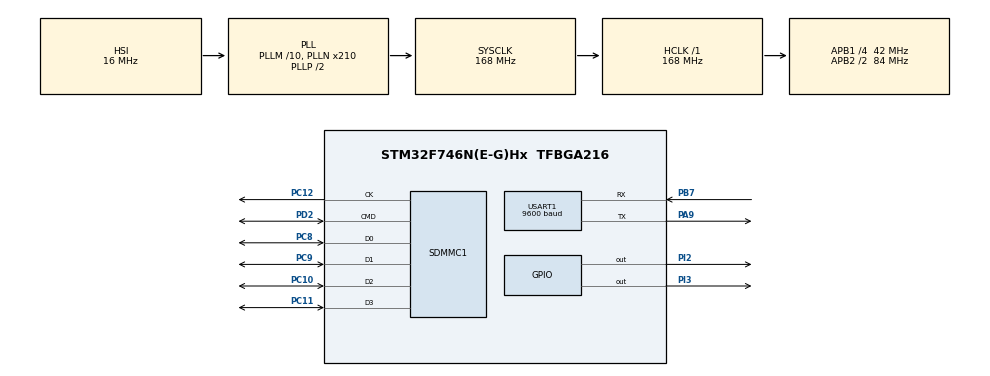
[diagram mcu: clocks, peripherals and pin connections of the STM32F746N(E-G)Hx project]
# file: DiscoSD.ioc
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FREERTOS.Tasks01=defaultTask,0,128,StartDefaultTask
Mcu.Family=STM32F7
Mcu.Name=STM32F746N(E-G)Hx
Mcu.Package=TFBGA216
NVIC.PriorityGroup=NVIC_PRIORITYGROUP_4
PA9.Mode=Asynchronous
PA9.Signal=USART1_TX
PB7.Mode=Asynchronous
PB7.Signal=USART1_RX
PC10.Mode=SD_4_bits_Wide_bus
PC10.Signal=SDMMC1_D2
PC11.Mode=SD_4_bits_Wide_bus
PC11.Signal=SDMMC1_D3
PC12.Mode=SD_4_bits_Wide_bus
PC12.Signal=SDMMC1_CK
PC8.Mode=SD_4_bits_Wide_bus
PC8.Signal=SDMMC1_D0
PC9.Mode=SD_4_bits_Wide_bus
PC9.Signal=SDMMC1_D1
PD2.Mode=SD_4_bits_Wide_bus
PD2.Signal=SDMMC1_CMD
PI2.Signal=GPIO_Output
PI3.Signal=GPIO_Output
ProjectManager.TargetToolchain=SW4STM32
RCC.AHBFreq_Value=168000000
RCC.APB1CLKDivider=RCC_HCLK_DIV4
RCC.APB1Freq_Value=42000000
RCC.APB1TimFreq_Value=84000000
RCC.APB2CLKDivider=RCC_HCLK_DIV2
RCC.APB2Freq_Value=84000000
RCC.APB2TimFreq_Value=168000000
RCC.CortexFreq_Value=168000000
RCC.HCLKFreq_Value=168000000
RCC.HSE_VALUE=25000000
RCC.HSI_VALUE=16000000
RCC.LSE_VALUE=32768
RCC.PLLM=10
RCC.PLLN=210
RCC.PLLSourceVirtual=RCC_PLLSOURCE_HSI
RCC.SYSCLKFreq_VALUE=168000000
RCC.SYSCLKSource=RCC_SYSCLKSOURCE_PLLCLK
RCC.USBFreq_Value=168000000
RCC.VCOOutputFreq_Value=336000000
SDMMC1.BusWide=SDMMC_BUS_WIDE_1B
SDMMC1.WideMode=SDMMC_BUS_WIDE_4B
USART1.BaudRate=9600
USART1.WordLength=UART_WORDLENGTH_8B
VP_FATFS_VS_SDIO.Mode=SDIO
VP_FREERTOS_VS_ENABLE.Mode=Enabled
board=STM32F746G-DISCO

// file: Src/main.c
/**
  ******************************************************************************
  * File Name          : main.c
  * Description        : Main program body
  ******************************************************************************
  *
  * COPYRIGHT(c) 2016 STMicroelectronics
  *
  * Redistribution and use in source and binary forms, with or without modification,
  * are permitted provided that the following conditions are met:
  *   1. Redistributions of source code must retain the above copyright notice,
  *      this list of conditions and the following disclaimer.
  *   2. Redistributions in binary form must reproduce the above copyright notice,
  *      this list of conditions and the following disclaimer in the documentation
  *      and/or other materials provided with the distribution.
  *   3. Neither the name of STMicroelectronics nor the names of its contributors
  *      may be used to endorse or promote products derived from this software
  *      without specific prior written permission.
  *
  * THIS SOFTWARE IS PROVIDED BY THE COPYRIGHT HOLDERS AND CONTRIBUTORS "AS IS"
  * AND ANY EXPRESS OR IMPLIED WARRANTIES, INCLUDING, BUT NOT LIMITED TO, THE
  * IMPLIED WARRANTIES OF MERCHANTABILITY AND FITNESS FOR A PARTICULAR PURPOSE ARE
  * DISCLAIMED. IN NO EVENT SHALL THE COPYRIGHT HOLDER OR CONTRIBUTORS BE LIABLE
  * FOR ANY DIRECT, INDIRECT, INCIDENTAL, SPECIAL, EXEMPLARY, OR CONSEQUENTIAL
  * DAMAGES (INCLUDING, BUT NOT LIMITED TO, PROCUREMENT OF SUBSTITUTE GOODS OR
  * SERVICES; LOSS OF USE, DATA, OR PROFITS; OR BUSINESS INTERRUPTION) HOWEVER
  * CAUSED AND ON ANY THEORY OF LIABILITY, WHETHER IN CONTRACT, STRICT LIABILITY,
  * OR TORT (INCLUDING NEGLIGENCE OR OTHERWISE) ARISING IN ANY WAY OUT OF THE USE
  * OF THIS SOFTWARE, EVEN IF ADVISED OF THE POSSIBILITY OF SUCH DAMAGE.
  *
  ******************************************************************************
  */
#include "stm32f7xx_hal.h"
#include "cmsis_os.h"
#include "fatfs.h"
#include "globalfunctions.h"

SD_HandleTypeDef hsd1;
HAL_SD_CardInfoTypedef SDCardInfo1;

//UART_HandleTypeDef huart1;

osThreadId defaultTaskHandle;

/* USER CODE BEGIN PV */
/* Private variables ---------------------------------------------------------*/

/* USER CODE END PV */

void SystemClock_Config(void);
static void MX_GPIO_Init(void);
static void MX_SDMMC1_SD_Init(void);
//static void MX_USART1_UART_Init(void);
void StartDefaultTask(void const * argument);
static void CPU_CACHE_Enable(void);

/* USER CODE BEGIN PFP */
/* Private function prototypes -----------------------------------------------*/
//static void strToUART(char * str);
/* USER CODE END PFP */

int main(void)
{
	CPU_CACHE_Enable();

  /* MCU Configuration----------------------------------------------------------*/

  /* Reset of all peripherals, Initializes the Flash interface and the Systick. */
  HAL_Init();

  /* Configure the system clock */
  SystemClock_Config();

  /* Initialize all configured peripherals */
  MX_GPIO_Init();
  MX_SDMMC1_SD_Init();
  MX_USART1_UART_Init();

  /* Create the thread(s) */
  /* definition and creation of defaultTask */
  osThreadDef(defaultTask, StartDefaultTask, osPriorityNormal, 0, 8*configMINIMAL_STACK_SIZE);
  defaultTaskHandle = osThreadCreate(osThread(defaultTask), NULL);

  /* Start scheduler */
  osKernelStart();

  /* We should never get here as control is now taken by the scheduler */

  /* Infinite loop */
  while (1)
  {

  }

}

/** System Clock Configuration
*/
void SystemClock_Config(void)
{

  RCC_OscInitTypeDef RCC_OscInitStruct;
  RCC_ClkInitTypeDef RCC_ClkInitStruct;
  RCC_PeriphCLKInitTypeDef PeriphClkInitStruct;

  __PWR_CLK_ENABLE();

  __HAL_PWR_VOLTAGESCALING_CONFIG(PWR_REGULATOR_VOLTAGE_SCALE2);

  RCC_OscInitStruct.OscillatorType = RCC_OSCILLATORTYPE_HSI;
  RCC_OscInitStruct.HSIState = RCC_HSI_ON;
  RCC_OscInitStruct.HSICalibrationValue = 16;
  RCC_OscInitStruct.PLL.PLLState = RCC_PLL_ON;
  RCC_OscInitStruct.PLL.PLLSource = RCC_PLLSOURCE_HSI;
  RCC_OscInitStruct.PLL.PLLM = 10;
  RCC_OscInitStruct.PLL.PLLN = 210;
  RCC_OscInitStruct.PLL.PLLP = RCC_PLLP_DIV2;
  RCC_OscInitStruct.PLL.PLLQ = 2;
  HAL_RCC_OscConfig(&RCC_OscInitStruct);

  RCC_ClkInitStruct.ClockType = RCC_CLOCKTYPE_HCLK|RCC_CLOCKTYPE_SYSCLK
                              |RCC_CLOCKTYPE_PCLK1|RCC_CLOCKTYPE_PCLK2;
  RCC_ClkInitStruct.SYSCLKSource = RCC_SYSCLKSOURCE_PLLCLK;
  RCC_ClkInitStruct.AHBCLKDivider = RCC_SYSCLK_DIV1;
  RCC_ClkInitStruct.APB1CLKDivider = RCC_HCLK_DIV4;
  RCC_ClkInitStruct.APB2CLKDivider = RCC_HCLK_DIV2;
  HAL_RCC_ClockConfig(&RCC_ClkInitStruct, FLASH_LATENCY_5);

  PeriphClkInitStruct.PeriphClockSelection = RCC_PERIPHCLK_USART1|RCC_PERIPHCLK_SDMMC1;
  PeriphClkInitStruct.Usart1ClockSelection = RCC_USART1CLKSOURCE_PCLK2;
  PeriphClkInitStruct.Sdmmc1ClockSelection = RCC_SDMMC1CLKSOURCE_SYSCLK;
  HAL_RCCEx_PeriphCLKConfig(&PeriphClkInitStruct);

  HAL_SYSTICK_Config(HAL_RCC_GetHCLKFreq()/1000);

  HAL_SYSTICK_CLKSourceConfig(SYSTICK_CLKSOURCE_HCLK);

  /* SysTick_IRQn interrupt configuration */
  HAL_NVIC_SetPriority(SysTick_IRQn, 15, 0);
}

static void CPU_CACHE_Enable(void)
{
  /* Enable I-Cache */
  SCB_EnableICache();

  /* Enable D-Cache */
  SCB_EnableDCache();
}

/* SDMMC1 init function */
void MX_SDMMC1_SD_Init(void)
{

  hsd1.Instance = SDMMC1;
  hsd1.Init.ClockEdge = SDMMC_CLOCK_EDGE_RISING;
  hsd1.Init.ClockBypass = SDMMC_CLOCK_BYPASS_DISABLE;
  hsd1.Init.ClockPowerSave = SDMMC_CLOCK_POWER_SAVE_DISABLE;
  hsd1.Init.BusWide = SDMMC_BUS_WIDE_1B;
  hsd1.Init.HardwareFlowControl = SDMMC_HARDWARE_FLOW_CONTROL_DISABLE;
  hsd1.Init.ClockDiv = 0;
  HAL_SD_Init(&hsd1, &SDCardInfo1);

  HAL_SD_WideBusOperation_Config(&hsd1, SDMMC_BUS_WIDE_4B);

}

/** Pinout Configuration
*/
void MX_GPIO_Init(void)
{

  /* GPIO Ports Clock Enable */
  __GPIOC_CLK_ENABLE();
  __GPIOB_CLK_ENABLE();
  __GPIOD_CLK_ENABLE();
  __GPIOA_CLK_ENABLE();
  __GPIOI_CLK_ENABLE();

  GPIO_InitTypeDef GPIO_InitStruct;
  /*Configure GPIO pins : PI3 PI2 */
  GPIO_InitStruct.Pin = GPIO_PIN_3|GPIO_PIN_2;
  GPIO_InitStruct.Mode = GPIO_MODE_OUTPUT_PP;
  GPIO_InitStruct.Pull = GPIO_NOPULL;
  GPIO_InitStruct.Speed = GPIO_SPEED_LOW;
  HAL_GPIO_Init(GPIOI, &GPIO_InitStruct);
}

/* StartDefaultTask function */
void StartDefaultTask(void const * argument)
{
  /* init code for FATFS */
  MX_FATFS_Init();

  /* USER CODE BEGIN 5 */
  HAL_GPIO_WritePin(GPIOI, GPIO_PIN_2, GPIO_PIN_RESET);
  /* Infinite loop */
  for(;;)
  {
	  HAL_GPIO_TogglePin(GPIOI, GPIO_PIN_3);
    osDelay(100);
  }
  /* USER CODE END 5 */
}

/************************ (C) COPYRIGHT STMicroelectronics *****END OF FILE****/
